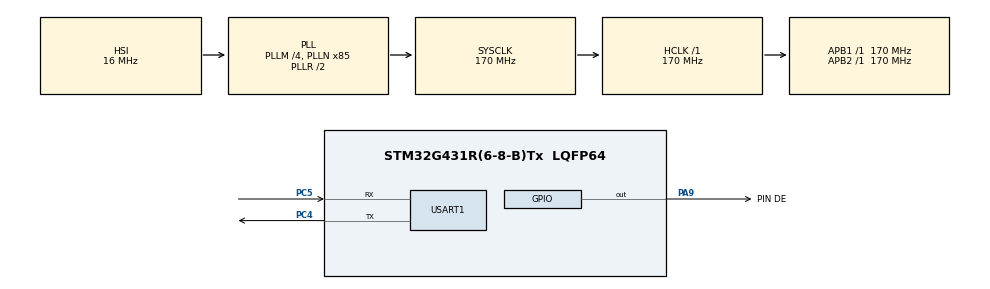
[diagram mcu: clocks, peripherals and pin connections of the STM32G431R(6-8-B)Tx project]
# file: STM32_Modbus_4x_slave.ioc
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Mcu.Family=STM32G4
Mcu.Name=STM32G431R(6-8-B)Tx
Mcu.Package=LQFP64
NUCLEO-G431RB.VCP=true
NVIC.PriorityGroup=NVIC_PRIORITYGROUP_4
NVIC.TIM2_IRQn=true\:0\:0\:false\:false\:true\:true\:true\:true
NVIC.USART1_IRQn=true\:0\:0\:false\:false\:true\:true\:true\:true
PA13.GPIO_Label=T_SWDIO
PA13.Signal=SYS_JTMS-SWDIO
PA14.GPIO_Label=T_SWCLK
PA14.Signal=SYS_JTCK-SWCLK
PA2.Signal=LPUART1_TX
PA3.Signal=LPUART1_RX
PA9.GPIO_Label=PIN DE
PA9.Signal=GPIO_Output
PB3.GPIO_Label=T_SWO
PB3.Signal=SYS_JTDO-SWO
PC14-OSC32_IN.GPIO_Label=RCC_OSC32_OUT
PC14-OSC32_IN.Signal=RCC_OSC32_IN
PC15-OSC32_OUT.GPIO_Label=RCC_OSC32_OUT
PC15-OSC32_OUT.Signal=RCC_OSC32_OUT
PC4.Mode=Asynchronous
PC4.Signal=USART1_TX
PC5.Mode=Asynchronous
PC5.Signal=USART1_RX
PF0-OSC_IN.GPIO_Label=RCC_OSC_IN
PF0-OSC_IN.Signal=RCC_OSC_IN
PF1-OSC_OUT.GPIO_Label=RCC_OSC_OUT
PF1-OSC_OUT.Signal=RCC_OSC_OUT
ProjectManager.HeapSize=0x200
ProjectManager.StackSize=0x400
ProjectManager.TargetToolchain=STM32CubeIDE
RCC.ADC12Freq_Value=170000000
RCC.AHBFreq_Value=170000000
RCC.APB1Freq_Value=170000000
RCC.APB1TimFreq_Value=170000000
RCC.APB2Freq_Value=170000000
RCC.APB2TimFreq_Value=170000000
RCC.CortexFreq_Value=170000000
RCC.EXTERNAL_CLOCK_VALUE=12288000
RCC.HCLKFreq_Value=170000000
RCC.HSE_VALUE=24000000
RCC.HSI48_VALUE=48000000
RCC.HSI_VALUE=16000000
RCC.LSE_VALUE=32768
RCC.PLLM=RCC_PLLM_DIV4
RCC.PLLN=85
RCC.RTCClockSelection=RCC_RTCCLKSOURCE_LSE
RCC.SYSCLKFreq_VALUE=170000000
RCC.SYSCLKSource=RCC_SYSCLKSOURCE_PLLCLK
RCC.USBFreq_Value=170000000
RCC.VCOOutputFreq_Value=340000000
USART1.VirtualMode-Asynchronous=VM_ASYNC
VP_NUCLEO-G431RB_VS_BSP_COMMON.Mode=COMMON
VP_SYS_VS_DBSignals.Mode=DisableDeadBatterySignals
VP_TIM2_VS_ClockSourceINT.Mode=Internal
board=NUCLEO-G431RB

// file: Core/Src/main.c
/* USER CODE BEGIN Header */
/**
  ******************************************************************************
  * @file           : main.c
  * @brief          : Main program body
  ******************************************************************************
  * @attention
  *
  * Copyright (c) 2025 STMicroelectronics.
  * All rights reserved.
  *
  * This software is licensed under terms that can be found in the LICENSE file
  * in the root directory of this software component.
  * If no LICENSE file comes with this software, it is provided AS-IS.
  *
  ******************************************************************************
  */
/* USER CODE END Header */
#include "main.h"

TIM_HandleTypeDef htim2;

UART_HandleTypeDef huart1;

void SystemClock_Config(void);
static void MX_GPIO_Init(void);
static void MX_USART1_UART_Init(void);
static void MX_TIM2_Init(void);

int main(void)
{

  /* MCU Configuration--------------------------------------------------------*/

  /* Reset of all peripherals, Initializes the Flash interface and the Systick. */
  HAL_Init();

  /* Configure the system clock */
  SystemClock_Config();

  /* Initialize all configured peripherals */
  MX_GPIO_Init();
  MX_USART1_UART_Init();
  MX_TIM2_Init();
  /* USER CODE BEGIN 2 */
  MB_Holding_reg[0] = 1;
  MB_Holding_reg[1] = 2;
  MB_Holding_reg[2] = 3;
  MB_Holding_reg[3] = 4;
  MB_Holding_reg[4] = 5;
  MB_Holding_reg[5] = 6;
  MB_Holding_reg[6] = 7;
  MB_Holding_reg[7] = 8;
  MB_Holding_reg[8] = 9;
  MB_Holding_reg[9] = 10;
  MB_Holding_reg[10] = 11;
  HAL_UART_Receive_IT(&huart1 , &rxData , 1);
  /* USER CODE END 2 */

  /* Infinite loop */
  /* USER CODE BEGIN WHILE */
  while (1)
  {
	if(frameReady)
    {
		Handle_MB_TX();
	}
    /* USER CODE END WHILE */

  }
}

void SystemClock_Config(void)
{
  RCC_OscInitTypeDef RCC_OscInitStruct = {0};
  RCC_ClkInitTypeDef RCC_ClkInitStruct = {0};

  /** Configure the main internal regulator output voltage
  */
  HAL_PWREx_ControlVoltageScaling(PWR_REGULATOR_VOLTAGE_SCALE1_BOOST);

  /** Initializes the RCC Oscillators according to the specified parameters
  * in the RCC_OscInitTypeDef structure.
  */
  RCC_OscInitStruct.OscillatorType = RCC_OSCILLATORTYPE_HSI;
  RCC_OscInitStruct.HSIState = RCC_HSI_ON;
  RCC_OscInitStruct.HSICalibrationValue = RCC_HSICALIBRATION_DEFAULT;
  RCC_OscInitStruct.PLL.PLLState = RCC_PLL_ON;
  RCC_OscInitStruct.PLL.PLLSource = RCC_PLLSOURCE_HSI;
  RCC_OscInitStruct.PLL.PLLM = RCC_PLLM_DIV4;
  RCC_OscInitStruct.PLL.PLLN = 85;
  RCC_OscInitStruct.PLL.PLLP = RCC_PLLP_DIV2;
  RCC_OscInitStruct.PLL.PLLQ = RCC_PLLQ_DIV2;
  RCC_OscInitStruct.PLL.PLLR = RCC_PLLR_DIV2;
  if (HAL_RCC_OscConfig(&RCC_OscInitStruct) != HAL_OK)
  {
    Error_Handler();
  }

  /** Initializes the CPU, AHB and APB buses clocks
  */
  RCC_ClkInitStruct.ClockType = RCC_CLOCKTYPE_HCLK|RCC_CLOCKTYPE_SYSCLK
                              |RCC_CLOCKTYPE_PCLK1|RCC_CLOCKTYPE_PCLK2;
  RCC_ClkInitStruct.SYSCLKSource = RCC_SYSCLKSOURCE_PLLCLK;
  RCC_ClkInitStruct.AHBCLKDivider = RCC_SYSCLK_DIV1;
  RCC_ClkInitStruct.APB1CLKDivider = RCC_HCLK_DIV1;
  RCC_ClkInitStruct.APB2CLKDivider = RCC_HCLK_DIV1;

  if (HAL_RCC_ClockConfig(&RCC_ClkInitStruct, FLASH_LATENCY_4) != HAL_OK)
  {
    Error_Handler();
  }
}

static void MX_TIM2_Init(void)
{

  TIM_ClockConfigTypeDef sClockSourceConfig = {0};
  TIM_MasterConfigTypeDef sMasterConfig = {0};

  htim2.Instance = TIM2;
  htim2.Init.Prescaler = 0;
  htim2.Init.CounterMode = TIM_COUNTERMODE_UP;
  htim2.Init.Period = 4294967295;
  htim2.Init.ClockDivision = TIM_CLOCKDIVISION_DIV1;
  htim2.Init.AutoReloadPreload = TIM_AUTORELOAD_PRELOAD_DISABLE;
  if (HAL_TIM_Base_Init(&htim2) != HAL_OK)
  {
    Error_Handler();
  }
  sClockSourceConfig.ClockSource = TIM_CLOCKSOURCE_INTERNAL;
  if (HAL_TIM_ConfigClockSource(&htim2, &sClockSourceConfig) != HAL_OK)
  {
    Error_Handler();
  }
  sMasterConfig.MasterOutputTrigger = TIM_TRGO_RESET;
  sMasterConfig.MasterSlaveMode = TIM_MASTERSLAVEMODE_DISABLE;
  if (HAL_TIMEx_MasterConfigSynchronization(&htim2, &sMasterConfig) != HAL_OK)
  {
    Error_Handler();
  }
  /* USER CODE BEGIN TIM2_Init 2 */
  HAL_NVIC_SetPriority(TIM2_IRQn, 1, 0);
  HAL_NVIC_EnableIRQ(TIM2_IRQn);
  /* USER CODE END TIM2_Init 2 */

}

static void MX_USART1_UART_Init(void)
{

  huart1.Instance = USART1;
  huart1.Init.BaudRate = 57600;
  huart1.Init.WordLength = UART_WORDLENGTH_8B;
  huart1.Init.StopBits = UART_STOPBITS_1;
  huart1.Init.Parity = UART_PARITY_NONE;
  huart1.Init.Mode = UART_MODE_TX_RX;
  huart1.Init.HwFlowCtl = UART_HWCONTROL_NONE;
  huart1.Init.OverSampling = UART_OVERSAMPLING_16;
  huart1.Init.OneBitSampling = UART_ONE_BIT_SAMPLE_DISABLE;
  huart1.Init.ClockPrescaler = UART_PRESCALER_DIV1;
  huart1.AdvancedInit.AdvFeatureInit = UART_ADVFEATURE_NO_INIT;
  if (HAL_UART_Init(&huart1) != HAL_OK)
  {
    Error_Handler();
  }
  if (HAL_UARTEx_SetTxFifoThreshold(&huart1, UART_TXFIFO_THRESHOLD_1_8) != HAL_OK)
  {
    Error_Handler();
  }
  if (HAL_UARTEx_SetRxFifoThreshold(&huart1, UART_RXFIFO_THRESHOLD_1_8) != HAL_OK)
  {
    Error_Handler();
  }
  if (HAL_UARTEx_DisableFifoMode(&huart1) != HAL_OK)
  {
    Error_Handler();
  }
  /* USER CODE BEGIN USART1_Init 2 */
  HAL_NVIC_SetPriority(USART1_IRQn, 0, 0);
  HAL_NVIC_EnableIRQ(USART1_IRQn);
  /* USER CODE END USART1_Init 2 */

}

static void MX_GPIO_Init(void)
{
  GPIO_InitTypeDef GPIO_InitStruct = {0};

  /* GPIO Ports Clock Enable */
  __HAL_RCC_GPIOC_CLK_ENABLE();
  __HAL_RCC_GPIOF_CLK_ENABLE();
  __HAL_RCC_GPIOA_CLK_ENABLE();
  __HAL_RCC_GPIOB_CLK_ENABLE();

  /*Configure GPIO pin Output Level */
  HAL_GPIO_WritePin(PIN_DE_GPIO_Port, PIN_DE_Pin, GPIO_PIN_RESET);

  /*Configure GPIO pin : PIN_DE_Pin */
  GPIO_InitStruct.Pin = PIN_DE_Pin;
  GPIO_InitStruct.Mode = GPIO_MODE_OUTPUT_PP;
  GPIO_InitStruct.Pull = GPIO_NOPULL;
  GPIO_InitStruct.Speed = GPIO_SPEED_FREQ_LOW;
  HAL_GPIO_Init(PIN_DE_GPIO_Port, &GPIO_InitStruct);

}

void Error_Handler(void)
{
  __disable_irq();
  while (1)
  {
  }
}
